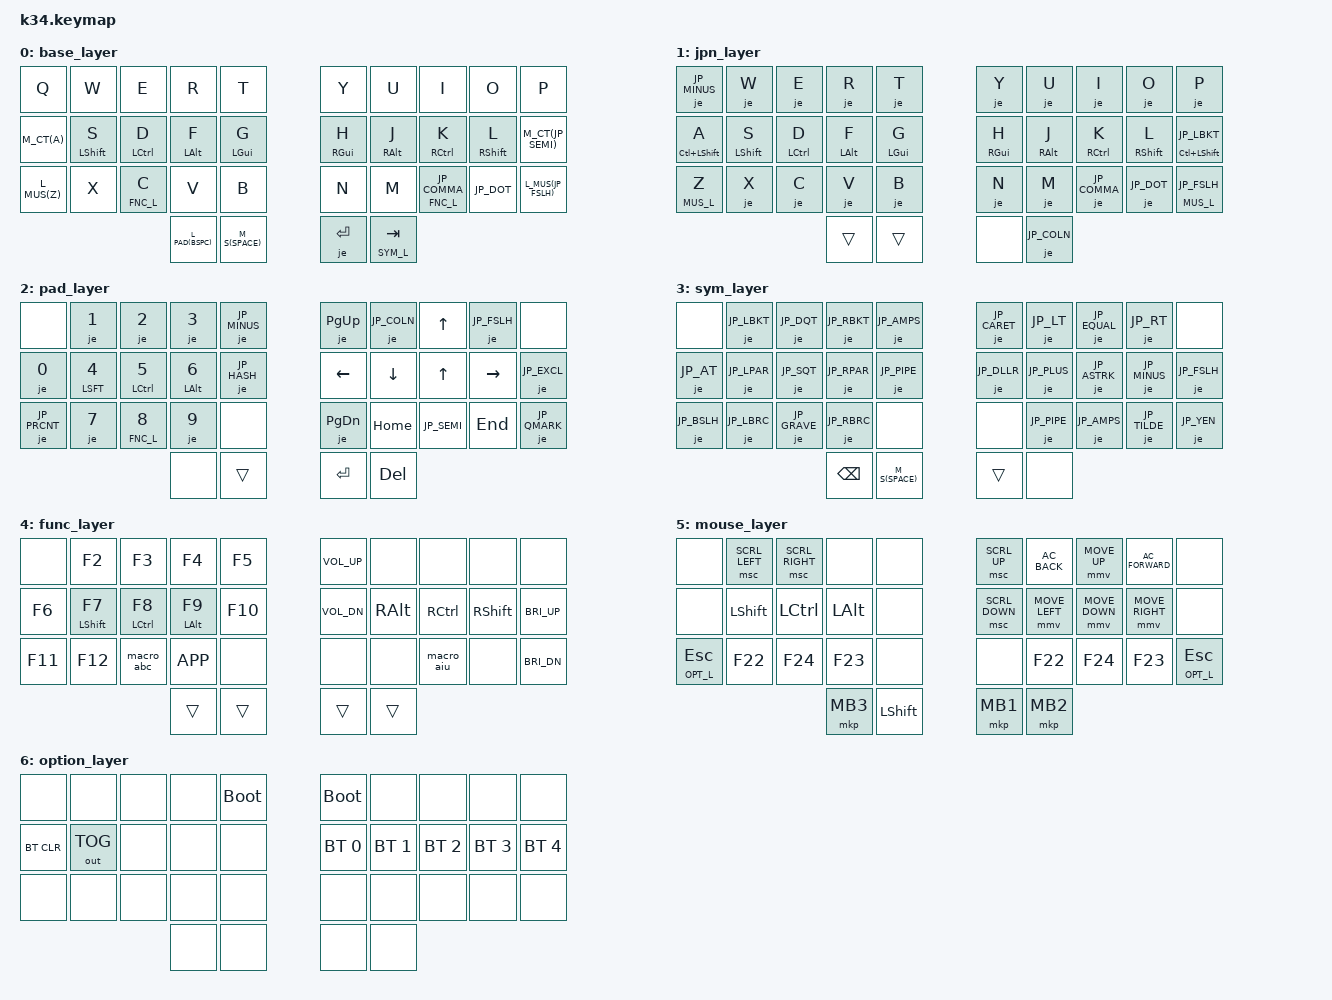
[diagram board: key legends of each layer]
/*
 * Copyright (c) 2020 The ZMK Contributors
 *
 * SPDX-License-Identifier: MIT
 */

#include <behaviors.dtsi>
#include <dt-bindings/zmk/keys.h>
#include <dt-bindings/zmk/bt.h>
#include <dt-bindings/zmk/outputs.h>
#include <dt-bindings/zmk/jp_enter.h>

#define ZMK_POINTING_DEFAULT_MOVE_VAL 2900  // default: 600
#define ZMK_POINTING_DEFAULT_SCRL_VAL 30    // default: 10
#include <dt-bindings/zmk/pointing.h>

#define BAS_L 0
#define JPN_L 1
#define PAD_L 2
#define SYM_L 3
#define FNC_L 4
#define MUS_L 5
#define OPT_L 6

#define ___     &trans
#define XXX     &none
#define PRESSED &none

#define M_CT(k) &mt LC(LSHFT) k
#define M_S(k) &mt LSHFT k
#define L_PAD(k) &lt PAD_L k
#define L_MUS(k) &lt MUS_L k


&lt {
  flavor = "tap-preferred";
  tapping-term-ms = <180>;
  quick-tap-ms = <175>;
};
&mt {
  flavor = "tap-preferred";
  tapping-term-ms = <180>;
  quick-tap-ms = <175>;
};
&je {
  je-entry-layer = <JPN_L>;
};
&mmv {
  trigger-period-ms = <16>;
  time-to-max-speed-ms = <700>;
  acceleration-exponent = <1>;
};

/ {
  behaviors {
    jmt: my_jp_mod_tap {
      compatible = "zmk,behavior-hold-tap";
      #binding-cells = <2>;
      flavor = "tap-preferred";
      tapping-term-ms = <180>;
      quick-tap-ms = <175>;
      bindings = <&kp>, <&je>;
      display-name = "My Mod-Tap";
    };
  };
  behaviors {
    jlt: my_jp_layer_tap {
      compatible = "zmk,behavior-hold-tap";
      #binding-cells = <2>;
      flavor = "tap-preferred";
      tapping-term-ms = <180>;
      quick-tap-ms = <175>;
      bindings = <&mo>, <&je>;
      display-name = "My Layer-Tap";
    };
  };
};

/ {
  macros {
    ZMK_MACRO(macro_int5_esc,
      wait-ms = <1>;
      tap-ms = <1>;
      bindings = <&kp INT5>, <&kp LANG2>, <&kp ESC>;
    )
    ZMK_MACRO(macro_send_exit,
      wait-ms = <1>;
      tap-ms = <1>;
      bindings = <&kp E>, <&kp X>, <&kp I>, <&kp T>;
    )
    ZMK_MACRO(macro_abc,
      wait-ms = <1>;
      tap-ms = <1>;
      bindings = <&kp INT5>, <&kp LANG2>;
    )
    ZMK_MACRO(macro_aiu,
      wait-ms = <1>;
      tap-ms = <1>;
      bindings = <&kp INT4>, <&kp LANG1>;
    )
  };

  combos {
    compatible = "zmk,combos";

    cmb_tilde {
      key-positions = <7 8>;
      layers = <JPN_L>;
      bindings = <&je JP_TILDE>;
    };
    cmb_excl {
      key-positions = <12 23>;
      layers = <JPN_L>;
      bindings = <&je JP_EXCL>;
    };
    cmb_qmark {
      key-positions = <17 26>;
      layers = <JPN_L>;
      bindings = <&je JP_QMARK>;
    };
    cmb_coln {
      key-positions = <17 18>;
      layers = <BAS_L JPN_L>;
      bindings = <&je JP_COLN>;
    };
    cmb_stab {
      key-positions = <1 3>;
      layers = <BAS_L JPN_L>;
      bindings = <&kp LS(TAB)>;
    };
    cmb_dot {
      key-positions = <7 18>;
      layers = <BAS_L JPN_L>;
      bindings = <&je JP_DOT>;
    };
    cmb_comma {
      key-positions = <17 28>;
      layers = <BAS_L JPN_L>;
      bindings = <&je JP_COMMA>;
    };
    cmb_tab {
      key-positions = <11 13>;
      layers = <BAS_L JPN_L>;
      bindings = <&kp TAB>;
    };

    cmb_del {
      key-positions = <12 13>;
      layers = <BAS_L JPN_L>;
      bindings = <&kp DEL>;
    };

    cmb_int5_esc {
      key-positions = <16 17>;
      layers = <BAS_L>;
      bindings = <&macro_int5_esc>;
    };
    cmb_enter {
      key-positions = <16 18>;
      layers = <BAS_L JPN_L>;
      bindings = <&kp ENTER>;
    };
    cmb_under {
      key-positions = <27 28>;
      layers = <BAS_L JPN_L>;
      bindings = <&je JP_UNDER>;
    };

    cmb_esc {
      key-positions = <16 17>;
      layers = <JPN_L PAD_L>;
      bindings = <&kp ESC>;
    };

    combo_send_exit {
      key-positions = <10 21>;
      bindings = <&macro_send_exit>;
      layers = <BAS_L>;
    };

  };

  keymap {
    compatible = "zmk,keymap";
    //  |     0       |     1       |     2       |     3       |     4     |    |     5       |     6       |     7       |     8       |     9     |
    //  |    10       |    11       |    12       |    13       |    14     |    |    15       |    16       |    17       |    18       |    19     |
    //  |    20       |    21       |    22       |    23       |    24     |    |    25       |    26       |    27       |    28       |    29     |
    //                                            |    30       |    31     |    |    32       |    33       |

    base_layer {
      bindings = <
        &kp Q         &kp W         &kp E         &kp R         &kp T            &kp Y         &kp U         &kp I         &kp O         &kp P
        M_CT(A)       &mt LSHFT S   &mt LCTRL D   &mt LALT F    &mt LGUI G       &mt RGUI H    &mt RALT J    &mt RCTRL K   &mt RSHFT L   M_CT(JP_SEMI)
        L_MUS(Z)      &kp X         &lt FNC_L C   &kp V         &kp B            &kp N         &kp M    &lt FNC_L JP_COMMA &kp JP_DOT    L_MUS(JP_FSLH)
                                                  L_PAD(BSPC)   M_S(SPACE)       &je ENTER     &lt SYM_L TAB
      >;
    };

    jpn_layer {
      bindings = <
        &je JP_MINUS  &je W         &je E         &je R         &je T            &je Y         &je U         &je I         &je O         &je P
        &jmt LC(LSHFT) A  &jmt LSHFT S  &jmt LCTRL D  &jmt LALT F  &jmt LGUI G   &jmt RGUI H   &jmt RALT J   &jmt RCTRL K  &jmt RSHFT L  &jmt LC(LSHFT) JP_LBKT
        &jlt MUS_L Z  &je X         &je C         &je V         &je B            &je N         &je M         &je JP_COMMA  &je JP_DOT    &jlt MUS_L JP_FSLH
                                                  ___            ___             PRESSED       &je JP_COLN
      >;
    };

    pad_layer {
      bindings = <
        XXX           &je N1        &je N2        &je N3         &je JP_MINUS    &je PG_UP     &je JP_COLN   &kp UP        &je JP_FSLH   XXX
        &je N0        &jmt LSFT N4  &jmt LCTRL N5 &jmt LALT N6   &je JP_HASH     &kp LEFT      &kp DOWN      &kp UP        &kp RIGHT     &je JP_EXCL
        &je JP_PRCNT  &je N7        &jlt FNC_L N8 &je N9         XXX             &je PG_DN     &kp HOME      &kp JP_SEMI   &kp END       &je JP_QMARK
                                                  PRESSED        ___             &kp ENTER     &kp DEL
      >;
    };

    sym_layer {
      bindings = <
        XXX           &je JP_LBKT   &je JP_DQT    &je JP_RBKT   &je JP_AMPS      &je JP_CARET  &je JP_LT     &je JP_EQUAL  &je JP_RT     XXX
        &je JP_AT     &je JP_LPAR   &je JP_SQT    &je JP_RPAR   &je JP_PIPE      &je JP_DLLR   &je JP_PLUS   &je JP_ASTRK  &je JP_MINUS  &je JP_FSLH
        &je JP_BSLH   &je JP_LBRC   &je JP_GRAVE  &je JP_RBRC   XXX              XXX           &je JP_PIPE   &je JP_AMPS   &je JP_TILDE  &je JP_YEN
                                                  &kp BSPC      M_S(SPACE)       ___           PRESSED
      >;
    };

    func_layer {
      bindings = <
        XXX           &kp F2        &kp F3        &kp F4        &kp F5           &kp C_VOL_UP  XXX           XXX           XXX           XXX
        &kp F6        &mt LSHFT F7  &mt LCTRL F8  &mt LALT F9   &kp F10          &kp C_VOL_DN  &kp RALT      &kp RCTRL     &kp RSHFT     &kp C_BRI_UP
        &kp F11       &kp F12       &macro_abc    &kp K_APP     XXX              XXX           XXX           &macro_aiu    XXX           &kp C_BRI_DN
                                                  ___           ___              ___           ___
      >;
    };

    mouse_layer {
      bindings = <
        XXX        &msc SCRL_LEFT &msc SCRL_RIGHT XXX          XXX               &msc SCRL_UP  &kp C_AC_BACK &mmv MOVE_UP  &kp C_AC_FORWARD   XXX
        XXX           &kp LSHFT     &kp LCTRL     &kp LALT     XXX               &msc SCRL_DOWN &mmv MOVE_LEFT &mmv MOVE_DOWN &mmv MOVE_RIGHT XXX
        &lt OPT_L ESC &kp F22       &kp F24       &kp F23      XXX              XXX            &kp F22      &kp F24        &kp F23       &lt OPT_L ESC
                                                  &mkp MB3     &kp LSHFT         &mkp MB1      &mkp MB2
      >;
    };

    option_layer {
      bindings = <
        XXX           XXX           XXX           XXX         &bootloader    &bootloader       XXX           XXX           XXX           XXX
        &bt BT_CLR    &out OUT_TOG  XXX           XXX           XXX              &bt BT_SEL 0  &bt BT_SEL 1  &bt BT_SEL 2  &bt BT_SEL 3  &bt BT_SEL 4
        PRESSED       XXX           XXX           XXX           XXX              XXX           XXX           XXX           XXX           PRESSED
                                                  XXX           XXX              XXX           XXX
      >;
    };

  };  // keymap

};

